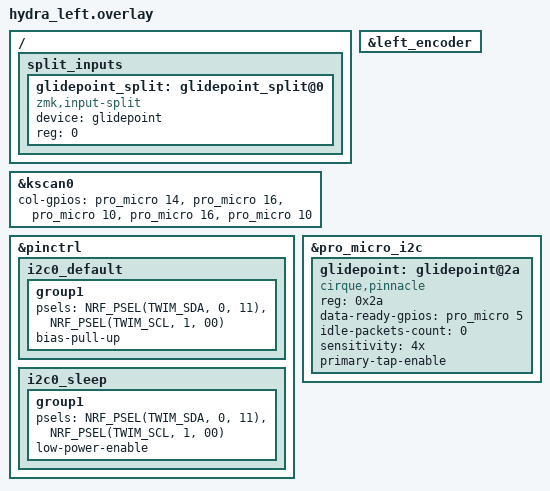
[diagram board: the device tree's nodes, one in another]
#include "hydra.dtsi"

&kscan0 {
    col-gpios
        = <&pro_micro 14 GPIO_ACTIVE_HIGH> // COL1 D14
        , <&pro_micro 16 GPIO_ACTIVE_HIGH> // COL2 D16
        , <&pro_micro 10 GPIO_ACTIVE_HIGH> // COL3 D10
        , <&pro_micro 16 GPIO_ACTIVE_HIGH> // COL4 TBD
        , <&pro_micro 10 GPIO_ACTIVE_HIGH> // COL5 TBD
        ;
};

&left_encoder { status = "okay"; };

&pinctrl {
    i2c0_default: i2c0_default {
        group1 {
            psels = <NRF_PSEL(TWIM_SDA, 0, 11)>, // D7 SDAT
                <NRF_PSEL(TWIM_SCL, 1, 00)>; // D6 SCLT
            bias-pull-up;
        };
    };
    i2c0_sleep: i2c0_sleep {
        group1 {
            psels = <NRF_PSEL(TWIM_SDA, 0, 11)>, // D7 SDAT
                <NRF_PSEL(TWIM_SCL, 1, 00)>; // D6 SCLT
            low-power-enable;
        };
    };
};

&pro_micro_i2c {
    status = "okay";
    glidepoint: glidepoint@2a {
        compatible = "cirque,pinnacle";
        status = "okay";
        reg = <0x2a>;
        data-ready-gpios = <&pro_micro 5 (GPIO_ACTIVE_HIGH)>; // D5 DRT
        idle-packets-count = <0>;
        sensitivity = "4x";
        primary-tap-enable;
    };
};

/ {
    split_inputs {
        #address-cells = <1>;
        #size-cells = <0>;

        glidepoint_split: glidepoint_split@0 {
            compatible = "zmk,input-split";
            device = <&glidepoint>;
            reg = <0>;
        };
    };
};
